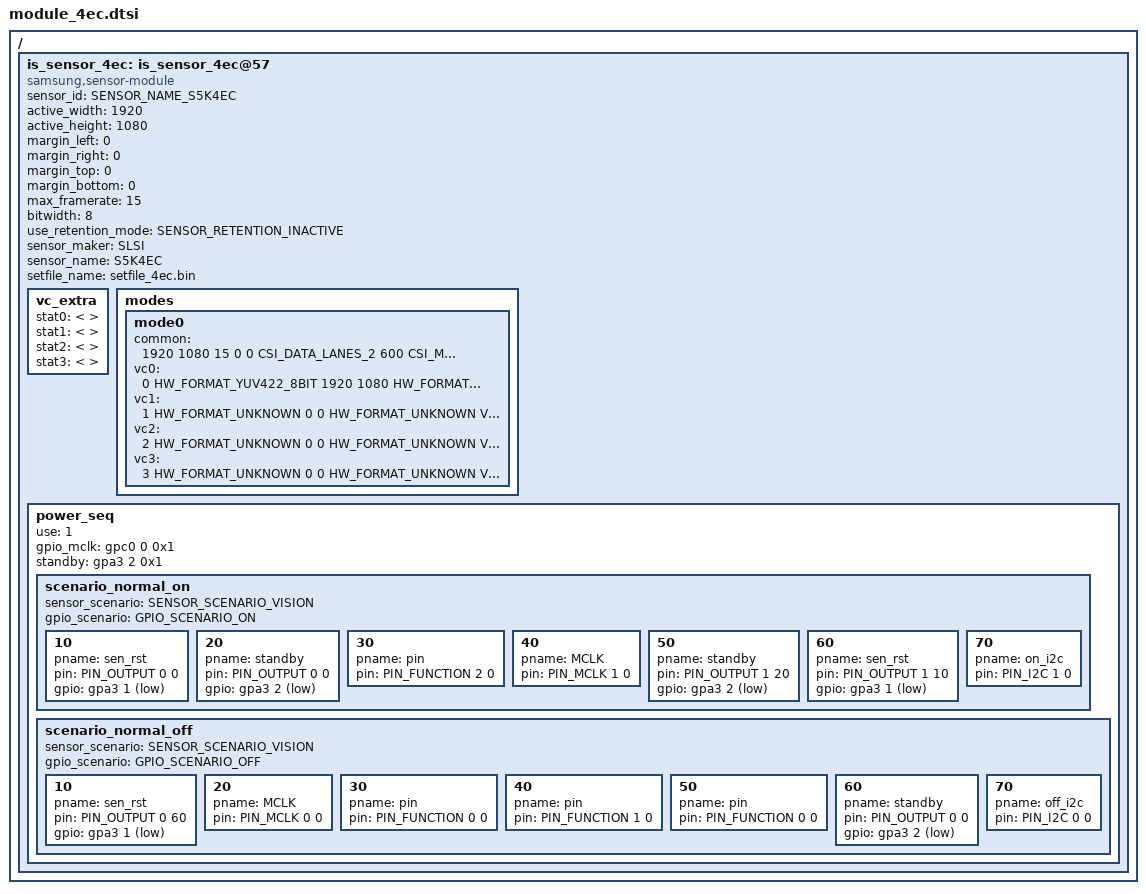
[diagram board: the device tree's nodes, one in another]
/*
 * SAMSUNG EXYNOSxxxx board camera device tree source
 *
 * Copyright (c) 2019 Samsung Electronics Co., Ltd.
 *		http://www.samsung.com
 *
 * This program is free software; you can redistribute it and/or modify
 * it under the terms of the GNU General Public License version 2 as
 * published by the Free Software Foundation.
 */

#include <dt-bindings/camera/exynos_is_dt.h>

/ {
	fragment@camera {
		target-path = "/";
		__overlay__ {
			is_sensor_4ec: is_sensor_4ec@57 {
				compatible = "samsung,sensor-module";

				/* common */
				sensor_id = <SENSOR_NAME_S5K4EC>;
				active_width = <1920>;
				active_height = <1080>;
				margin_left = <0>;
				margin_right = <0>;
				margin_top = <0>;
				margin_bottom = <0>;
				max_framerate = <15>;
				bitwidth = <8>;
				use_retention_mode = <SENSOR_RETENTION_INACTIVE>;
				sensor_maker = "SLSI";
				sensor_name = "S5K4EC";
				setfile_name = "setfile_4ec.bin";

				status = "okay";

				vc_extra {
					/* ex) statX = <stat_type, sensor_mode, max_width, max_height, max_element> */
					stat0 = </* not avaliable */>;	/* VC_BUF_DATA_TYPE_SENSOR_STAT1 */
					stat1 = </* not avaliable */>;	/* VC_BUF_DATA_TYPE_GENERAL_STAT1 */
					stat2 = </* not avaliable */>;	/* VC_BUF_DATA_TYPE_SENSOR_STAT2 */
					stat3 = </* not avaliable */>;	/* VC_BUF_DATA_TYPE_GENERAL_STAT2 */
				};

				/* sensor modes */
				modes {
						/* common = <width, height, fps, settle, mode, lane, speed, interleave, lrte, pd_mode> */
						/* vcX = <map, hwformat, width, height, hwformat, type, width, height> */
					mode0 {
						common = <1920 1080 15 0 0 CSI_DATA_LANES_2 600 CSI_MODE_VC_ONLY LRTE_DISABLE PD_NONE EX_NONE>;
						vc0 = </* in */ 0 HW_FORMAT_YUV422_8BIT 1920 1080	/* out */ HW_FORMAT_YUV422_8BIT VC_NOTHING 1920 1080>;
						vc1 = </* in */ 1 HW_FORMAT_UNKNOWN 0 0		/* out */ HW_FORMAT_UNKNOWN VC_NOTHING 0 0>;
						vc2 = </* in */ 2 HW_FORMAT_UNKNOWN 0 0		/* out */ HW_FORMAT_UNKNOWN VC_NOTHING 0 0>;
						vc3 = </* in */ 3 HW_FORMAT_UNKNOWN 0 0		/* out */ HW_FORMAT_UNKNOWN VC_NOTHING 0 0>;
					};
				};

				power_seq {
					use = <1>;
					gpio_mclk = <&gpc0 0 0x1>;
					standby = <&gpa3 2 0x1>;
					scenario_normal_on {
						sensor_scenario = <SENSOR_SCENARIO_VISION>;
						gpio_scenario = <GPIO_SCENARIO_ON>;
						/* A start node number should be over the 10 for reserved number 0~9. */
						/* pname = "name"; pin = <act value dealy voltage>; gpio = <gpx# # 0x1>; */
						10 { pname = "sen_rst"; pin = <PIN_OUTPUT 0 0>; gpio = <&gpa3 1 0x1>; };
						20 { pname = "standby"; pin = <PIN_OUTPUT 0 0>; gpio = <&gpa3 2 0x1>; };
						30 { pname = "pin"; pin = <PIN_FUNCTION 2 0>; };
						40 { pname = "MCLK"; pin = <PIN_MCLK 1 0>; };
						50 { pname = "standby"; pin = <PIN_OUTPUT 1 20>; gpio = <&gpa3 2 0x1>; };
						60 { pname = "sen_rst"; pin = <PIN_OUTPUT 1 10>; gpio = <&gpa3 1 0x1>; };
						70 { pname = "on_i2c"; pin = <PIN_I2C 1 0>; };
					};

					scenario_normal_off {
						sensor_scenario = <SENSOR_SCENARIO_VISION>;
						gpio_scenario = <GPIO_SCENARIO_OFF>;
						/* A start node number should be over the 10 for reserved number 0~9. */
						/* pname = "name"; pin = <act value dealy voltage>; gpio = <gpx# # 0x1>; */
						10 { pname = "sen_rst"; pin = <PIN_OUTPUT 0 60>; gpio = <&gpa3 1 0x1>; };
						20 { pname = "MCLK"; pin = <PIN_MCLK 0 0>; };
						30 { pname = "pin"; pin = <PIN_FUNCTION 0 0>; };
						40 { pname = "pin"; pin = <PIN_FUNCTION 1 0>; };
						50 { pname = "pin"; pin = <PIN_FUNCTION 0 0>; };
						60 { pname = "standby"; pin = <PIN_OUTPUT 0 0>; gpio = <&gpa3 2 0x1>; };
						70 { pname = "off_i2c"; pin = <PIN_I2C 0 0>; };
						/* need eeprom pin control */
					};
				};
			};
		}; /* end of __overlay__ */
	}; /* end of fragment */
}; /* end of root */
